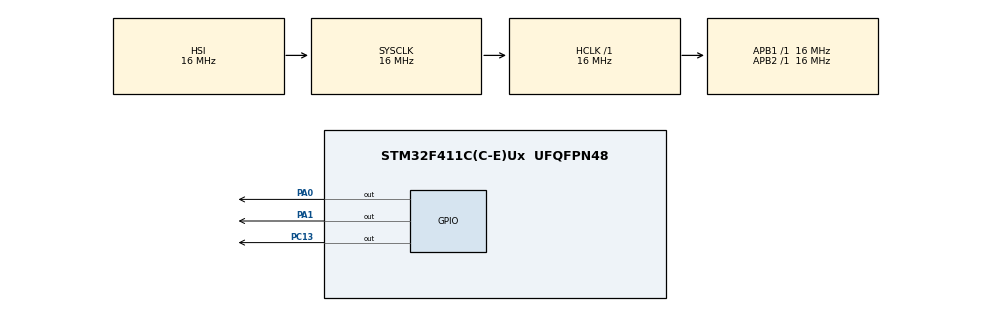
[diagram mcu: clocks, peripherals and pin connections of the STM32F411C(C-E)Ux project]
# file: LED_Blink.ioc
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Mcu.Family=STM32F4
Mcu.Name=STM32F411C(C-E)Ux
Mcu.Package=UFQFPN48
NVIC.PriorityGroup=NVIC_PRIORITYGROUP_4
PA0-WKUP.Signal=GPIO_Output
PA1.Signal=GPIO_Output
PA13.Mode=Serial_Wire
PA13.Signal=SYS_JTMS-SWDIO
PA14.Mode=Serial_Wire
PA14.Signal=SYS_JTCK-SWCLK
PC13-ANTI_TAMP.Signal=GPIO_Output
PH0\ -\ OSC_IN.Mode=HSE-External-Oscillator
PH0\ -\ OSC_IN.Signal=RCC_OSC_IN
PH1\ -\ OSC_OUT.Mode=HSE-External-Oscillator
PH1\ -\ OSC_OUT.Signal=RCC_OSC_OUT
ProjectManager.HeapSize=0x200
ProjectManager.StackSize=0x400
ProjectManager.TargetToolchain=CMake
RCC.AHBFreq_Value=16000000
RCC.APB1Freq_Value=16000000
RCC.APB2Freq_Value=16000000
RCC.CortexFreq_Value=16000000
RCC.HSE_VALUE=25000000
RCC.HSI_VALUE=16000000
RCC.LSE_VALUE=32768
RCC.SYSCLKFreq_VALUE=16000000
RCC.VCOOutputFreq_Value=192000000
TIM5.AutoReloadPreload=TIM_AUTORELOAD_PRELOAD_ENABLE
TIM5.Period=999
TIM5.Prescaler=99
VP_TIM5_VS_ClockSourceINT.Mode=Internal
board=custom

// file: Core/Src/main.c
/* USER CODE BEGIN Header */
/**
  ******************************************************************************
  * @file           : main.c
  * @brief          : Main program body
  ******************************************************************************
  * @attention
  *
  * Copyright (c) 2026 STMicroelectronics.
  * All rights reserved.
  *
  * This software is licensed under terms that can be found in the LICENSE file
  * in the root directory of this software component.
  * If no LICENSE file comes with this software, it is provided AS-IS.
  *
  ******************************************************************************
  */
/* USER CODE END Header */
#include "main.h"

TIM_HandleTypeDef htim5;

void SystemClock_Config(void);
static void MX_GPIO_Init(void);
static void MX_TIM5_Init(void);

/* USER CODE BEGIN 0 */
#define LED0_PIN GPIO_PIN_0
#define LED1_PIN GPIO_PIN_1

void Set_LED_State(uint8_t state) {
  HAL_GPIO_WritePin(GPIOA, LED0_PIN, (state & 0b10) ? GPIO_PIN_SET : GPIO_PIN_RESET);
  HAL_GPIO_WritePin(GPIOA, LED1_PIN, (state & 0b01) ? GPIO_PIN_SET : GPIO_PIN_RESET);
}

void LED_Blink(uint8_t state, uint8_t times) {
  while (times--) {
    Set_LED_State(state);
    HAL_Delay(500);
    Set_LED_State(0);
    HAL_Delay(500);
  }
}

void LED_RightToLeft(uint8_t times) {
  while (times--) {
    Set_LED_State(0b01); HAL_Delay(500);
    Set_LED_State(0b10); HAL_Delay(500);
    Set_LED_State(0b00); HAL_Delay(500);
  }
}

void LED_LeftToRight(uint8_t times) {
  while (times--) {
    Set_LED_State(0b10); HAL_Delay(500);
    Set_LED_State(0b01); HAL_Delay(500);
    Set_LED_State(0b00); HAL_Delay(500);
  }
}
/* USER CODE END 0 */

int main(void)
{

  /* MCU Configuration--------------------------------------------------------*/

  /* Reset of all peripherals, Initializes the Flash interface and the Systick. */
  HAL_Init();

  /* Configure the system clock */
  SystemClock_Config();

  /* Initialize all configured peripherals */
  MX_GPIO_Init();
  MX_TIM5_Init();
  /* USER CODE BEGIN 2 */

  // HAL_TIM_PWM_Start(&htim5, TIM_CHANNEL_1);
  // uint16_t pwm_val = 0;
  // uint8_t direction = 1;
  /* USER CODE END 2 */

  /* Infinite loop */
  /* USER CODE BEGIN WHILE */
  while (1)
  {
    // From one side to another side
    LED_RightToLeft(3);
    LED_LeftToRight(3);

    // Blink
    LED_Blink(0b10,2);
    LED_Blink(0b01,3);
    LED_Blink(0b11,4);

    // Display number by binary LED
    for (uint8_t i = 0; i < 4; i++) {
      Set_LED_State(i);
      HAL_Delay(1500);
    }
    Set_LED_State(0);
    HAL_Delay(1500);
    /* USER CODE END WHILE */

  }
}

void SystemClock_Config(void)
{
  RCC_OscInitTypeDef RCC_OscInitStruct = {0};
  RCC_ClkInitTypeDef RCC_ClkInitStruct = {0};

  /** Configure the main internal regulator output voltage
  */
  __HAL_RCC_PWR_CLK_ENABLE();
  __HAL_PWR_VOLTAGESCALING_CONFIG(PWR_REGULATOR_VOLTAGE_SCALE1);

  /** Initializes the RCC Oscillators according to the specified parameters
  * in the RCC_OscInitTypeDef structure.
  */
  RCC_OscInitStruct.OscillatorType = RCC_OSCILLATORTYPE_HSI;
  RCC_OscInitStruct.HSIState = RCC_HSI_ON;
  RCC_OscInitStruct.HSICalibrationValue = RCC_HSICALIBRATION_DEFAULT;
  RCC_OscInitStruct.PLL.PLLState = RCC_PLL_NONE;
  if (HAL_RCC_OscConfig(&RCC_OscInitStruct) != HAL_OK)
  {
    Error_Handler();
  }

  /** Initializes the CPU, AHB and APB buses clocks
  */
  RCC_ClkInitStruct.ClockType = RCC_CLOCKTYPE_HCLK|RCC_CLOCKTYPE_SYSCLK
                              |RCC_CLOCKTYPE_PCLK1|RCC_CLOCKTYPE_PCLK2;
  RCC_ClkInitStruct.SYSCLKSource = RCC_SYSCLKSOURCE_HSI;
  RCC_ClkInitStruct.AHBCLKDivider = RCC_SYSCLK_DIV1;
  RCC_ClkInitStruct.APB1CLKDivider = RCC_HCLK_DIV1;
  RCC_ClkInitStruct.APB2CLKDivider = RCC_HCLK_DIV1;

  if (HAL_RCC_ClockConfig(&RCC_ClkInitStruct, FLASH_LATENCY_0) != HAL_OK)
  {
    Error_Handler();
  }
}

static void MX_TIM5_Init(void)
{

  TIM_ClockConfigTypeDef sClockSourceConfig = {0};
  TIM_MasterConfigTypeDef sMasterConfig = {0};

  htim5.Instance = TIM5;
  htim5.Init.Prescaler = 99;
  htim5.Init.CounterMode = TIM_COUNTERMODE_UP;
  htim5.Init.Period = 999;
  htim5.Init.ClockDivision = TIM_CLOCKDIVISION_DIV1;
  htim5.Init.AutoReloadPreload = TIM_AUTORELOAD_PRELOAD_ENABLE;
  if (HAL_TIM_Base_Init(&htim5) != HAL_OK)
  {
    Error_Handler();
  }
  sClockSourceConfig.ClockSource = TIM_CLOCKSOURCE_INTERNAL;
  if (HAL_TIM_ConfigClockSource(&htim5, &sClockSourceConfig) != HAL_OK)
  {
    Error_Handler();
  }
  sMasterConfig.MasterOutputTrigger = TIM_TRGO_RESET;
  sMasterConfig.MasterSlaveMode = TIM_MASTERSLAVEMODE_DISABLE;
  if (HAL_TIMEx_MasterConfigSynchronization(&htim5, &sMasterConfig) != HAL_OK)
  {
    Error_Handler();
  }

}

static void MX_GPIO_Init(void)
{
  GPIO_InitTypeDef GPIO_InitStruct = {0};

  /* GPIO Ports Clock Enable */
  __HAL_RCC_GPIOC_CLK_ENABLE();
  __HAL_RCC_GPIOH_CLK_ENABLE();
  __HAL_RCC_GPIOA_CLK_ENABLE();

  /*Configure GPIO pin Output Level */
  HAL_GPIO_WritePin(GPIOC, GPIO_PIN_13, GPIO_PIN_RESET);

  /*Configure GPIO pin Output Level */
  HAL_GPIO_WritePin(GPIOA, GPIO_PIN_0|GPIO_PIN_1, GPIO_PIN_RESET);

  /*Configure GPIO pin : PC13 */
  GPIO_InitStruct.Pin = GPIO_PIN_13;
  GPIO_InitStruct.Mode = GPIO_MODE_OUTPUT_PP;
  GPIO_InitStruct.Pull = GPIO_NOPULL;
  GPIO_InitStruct.Speed = GPIO_SPEED_FREQ_LOW;
  HAL_GPIO_Init(GPIOC, &GPIO_InitStruct);

  /*Configure GPIO pins : PA0 PA1 */
  GPIO_InitStruct.Pin = GPIO_PIN_0|GPIO_PIN_1;
  GPIO_InitStruct.Mode = GPIO_MODE_OUTPUT_PP;
  GPIO_InitStruct.Pull = GPIO_NOPULL;
  GPIO_InitStruct.Speed = GPIO_SPEED_FREQ_LOW;
  HAL_GPIO_Init(GPIOA, &GPIO_InitStruct);

}

void Error_Handler(void)
{
  __disable_irq();
  while (1)
  {
  }
}
